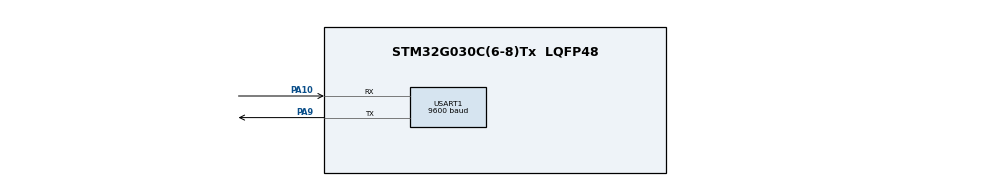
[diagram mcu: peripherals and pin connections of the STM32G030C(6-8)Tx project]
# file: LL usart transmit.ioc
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Mcu.Family=STM32G0
Mcu.Name=STM32G030C(6-8)Tx
Mcu.Package=LQFP48
PA10.Mode=Asynchronous
PA10.Signal=USART1_RX
PA13.Mode=Serial_Wire
PA13.Signal=SYS_SWDIO
PA14-BOOT0.Mode=Serial_Wire
PA14-BOOT0.Signal=SYS_SWCLK
PA9.Mode=Asynchronous
PA9.Signal=USART1_TX
PF0-OSC_IN\ (PF0).Mode=HSE-External-Oscillator
PF0-OSC_IN\ (PF0).Signal=RCC_OSC_IN
PF1-OSC_OUT\ (PF1).Mode=HSE-External-Oscillator
PF1-OSC_OUT\ (PF1).Signal=RCC_OSC_OUT
ProjectManager.HeapSize=0x200
ProjectManager.StackSize=0x400
ProjectManager.TargetToolchain=MDK-ARM V5.32
RCC.ADCFreq_Value=64000000
RCC.AHBFreq_Value=64000000
RCC.CortexFreq_Value=64000000
RCC.EXTERNAL_CLOCK_VALUE=12288000
RCC.HCLKFreq_Value=64000000
RCC.HSE_VALUE=8000000
RCC.HSI_VALUE=16000000
RCC.LSE_VALUE=32768
RCC.PLLN=16
RCC.PLLSourceVirtual=RCC_PLLSOURCE_HSE
RCC.SYSCLKFreq_VALUE=64000000
RCC.SYSCLKSource=RCC_SYSCLKSOURCE_PLLCLK
RCC.VCOOutputFreq_Value=128000000
USART1.BaudRate=9600
USART1.Mode=MODE_TX
USART1.VirtualMode-Asynchronous=VM_ASYNC
board=custom

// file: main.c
/* USER CODE BEGIN Header */
/**
  ******************************************************************************
  * @file           : main.c
  * @brief          : Main program body
  ******************************************************************************
  * @attention
  *
  * Copyright (c) 2023 STMicroelectronics.
  * All rights reserved.
  *
  * This software is licensed under terms that can be found in the LICENSE file
  * in the root directory of this software component.
  * If no LICENSE file comes with this software, it is provided AS-IS.
  *
  ******************************************************************************
  */
/* USER CODE END Header */
#include "main.h"

/* USER CODE BEGIN PV */
char word[5]="hello";
uint8_t i;
/* USER CODE END PV */

void SystemClock_Config(void);
static void MX_GPIO_Init(void);
static void MX_USART1_UART_Init(void);

int main(void)
{

  /* MCU Configuration--------------------------------------------------------*/

  /* Reset of all peripherals, Initializes the Flash interface and the Systick. */
  LL_APB2_GRP1_EnableClock(LL_APB2_GRP1_PERIPH_SYSCFG);
  LL_APB1_GRP1_EnableClock(LL_APB1_GRP1_PERIPH_PWR);

  /* SysTick_IRQn interrupt configuration */
  NVIC_SetPriority(SysTick_IRQn, 3);

  /* Configure the system clock */
  SystemClock_Config();

  /* Initialize all configured peripherals */
  MX_GPIO_Init();
  MX_USART1_UART_Init();
  /* USER CODE BEGIN 2 */
	for(i=0;i<sizeof(word);i++){
		LL_USART_TransmitData8(USART1,(char) word[i]);
		while(!LL_USART_IsActiveFlag_TXE(USART1));
	}

  /* USER CODE END 2 */

  /* Infinite loop */
  while (1)
  {

  }
}

void SystemClock_Config(void)
{
  LL_FLASH_SetLatency(LL_FLASH_LATENCY_2);
  while(LL_FLASH_GetLatency() != LL_FLASH_LATENCY_2)
  {
  }

  /* HSE configuration and activation */
  LL_RCC_HSE_Enable();
  while(LL_RCC_HSE_IsReady() != 1)
  {
  }

  /* Main PLL configuration and activation */
  LL_RCC_PLL_ConfigDomain_SYS(LL_RCC_PLLSOURCE_HSE, LL_RCC_PLLM_DIV_1, 16, LL_RCC_PLLR_DIV_2);
  LL_RCC_PLL_Enable();
  LL_RCC_PLL_EnableDomain_SYS();
  while(LL_RCC_PLL_IsReady() != 1)
  {
  }

  /* Set AHB prescaler*/
  LL_RCC_SetAHBPrescaler(LL_RCC_SYSCLK_DIV_1);

  /* Sysclk activation on the main PLL */
  LL_RCC_SetSysClkSource(LL_RCC_SYS_CLKSOURCE_PLL);
  while(LL_RCC_GetSysClkSource() != LL_RCC_SYS_CLKSOURCE_STATUS_PLL)
  {
  }

  /* Set APB1 prescaler*/
  LL_RCC_SetAPB1Prescaler(LL_RCC_APB1_DIV_1);

  LL_Init1msTick(64000000);

  /* Update CMSIS variable (which can be updated also through SystemCoreClockUpdate function) */
  LL_SetSystemCoreClock(64000000);
}

static void MX_USART1_UART_Init(void)
{

  LL_USART_InitTypeDef USART_InitStruct = {0};

  LL_GPIO_InitTypeDef GPIO_InitStruct = {0};

  LL_RCC_SetUSARTClockSource(LL_RCC_USART1_CLKSOURCE_PCLK1);

  /* Peripheral clock enable */
  LL_APB2_GRP1_EnableClock(LL_APB2_GRP1_PERIPH_USART1);

  LL_IOP_GRP1_EnableClock(LL_IOP_GRP1_PERIPH_GPIOA);
  /**USART1 GPIO Configuration
  PA9   ------> USART1_TX
  PA10   ------> USART1_RX
  */
  GPIO_InitStruct.Pin = LL_GPIO_PIN_9;
  GPIO_InitStruct.Mode = LL_GPIO_MODE_ALTERNATE;
  GPIO_InitStruct.Speed = LL_GPIO_SPEED_FREQ_LOW;
  GPIO_InitStruct.OutputType = LL_GPIO_OUTPUT_PUSHPULL;
  GPIO_InitStruct.Pull = LL_GPIO_PULL_NO;
  GPIO_InitStruct.Alternate = LL_GPIO_AF_1;
  LL_GPIO_Init(GPIOA, &GPIO_InitStruct);

  GPIO_InitStruct.Pin = LL_GPIO_PIN_10;
  GPIO_InitStruct.Mode = LL_GPIO_MODE_ALTERNATE;
  GPIO_InitStruct.Speed = LL_GPIO_SPEED_FREQ_LOW;
  GPIO_InitStruct.OutputType = LL_GPIO_OUTPUT_PUSHPULL;
  GPIO_InitStruct.Pull = LL_GPIO_PULL_NO;
  GPIO_InitStruct.Alternate = LL_GPIO_AF_1;
  LL_GPIO_Init(GPIOA, &GPIO_InitStruct);

  USART_InitStruct.PrescalerValue = LL_USART_PRESCALER_DIV1;
  USART_InitStruct.BaudRate = 9600;
  USART_InitStruct.DataWidth = LL_USART_DATAWIDTH_8B;
  USART_InitStruct.StopBits = LL_USART_STOPBITS_1;
  USART_InitStruct.Parity = LL_USART_PARITY_NONE;
  USART_InitStruct.TransferDirection = LL_USART_DIRECTION_TX;
  USART_InitStruct.HardwareFlowControl = LL_USART_HWCONTROL_NONE;
  USART_InitStruct.OverSampling = LL_USART_OVERSAMPLING_16;
  LL_USART_Init(USART1, &USART_InitStruct);
  LL_USART_SetTXFIFOThreshold(USART1, LL_USART_FIFOTHRESHOLD_1_8);
  LL_USART_SetRXFIFOThreshold(USART1, LL_USART_FIFOTHRESHOLD_1_8);
  LL_USART_DisableFIFO(USART1);
  LL_USART_ConfigAsyncMode(USART1);

  LL_USART_Enable(USART1);

  /* Polling USART1 initialisation */
  while(!(LL_USART_IsActiveFlag_TEACK(USART1)))
  {
  }

}

static void MX_GPIO_Init(void)
{

  /* GPIO Ports Clock Enable */
  LL_IOP_GRP1_EnableClock(LL_IOP_GRP1_PERIPH_GPIOF);
  LL_IOP_GRP1_EnableClock(LL_IOP_GRP1_PERIPH_GPIOA);

}

void Error_Handler(void)
{
  __disable_irq();
  while (1)
  {
  }
}
